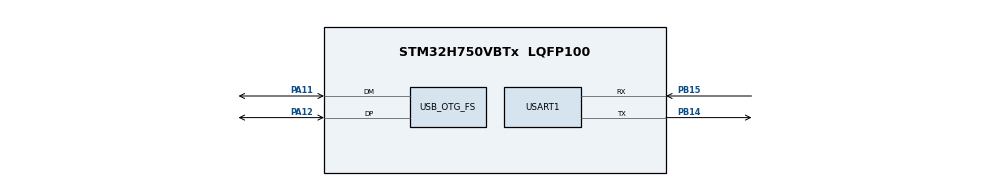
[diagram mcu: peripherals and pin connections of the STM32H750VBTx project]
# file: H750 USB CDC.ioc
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Mcu.Family=STM32H7
Mcu.Name=STM32H750VBTx
Mcu.Package=LQFP100
NVIC.OTG_FS_IRQn=true\:0\:0\:false\:false\:true\:false\:true
NVIC.PriorityGroup=NVIC_PRIORITYGROUP_4
NVIC.USART1_IRQn=true\:0\:0\:false\:false\:true\:true\:true
PA11.GPIO_Speed=GPIO_SPEED_FREQ_VERY_HIGH
PA11.Mode=Device_Only
PA11.Signal=USB_OTG_FS_DM
PA12.GPIO_Speed=GPIO_SPEED_FREQ_VERY_HIGH
PA12.Mode=Device_Only
PA12.Signal=USB_OTG_FS_DP
PA13\ (JTMS/SWDIO).Mode=Serial_Wire
PA13\ (JTMS/SWDIO).Signal=DEBUG_JTMS-SWDIO
PA14\ (JTCK/SWCLK).Mode=Serial_Wire
PA14\ (JTCK/SWCLK).Signal=DEBUG_JTCK-SWCLK
PB14.Mode=Asynchronous
PB14.Signal=USART1_TX
PB15.Mode=Asynchronous
PB15.Signal=USART1_RX
PH0-OSC_IN\ (PH0).Mode=HSE-External-Oscillator
PH0-OSC_IN\ (PH0).Signal=RCC_OSC_IN
PH1-OSC_OUT\ (PH1).Mode=HSE-External-Oscillator
PH1-OSC_OUT\ (PH1).Signal=RCC_OSC_OUT
ProjectManager.HeapSize=0x200
ProjectManager.StackSize=0x400
ProjectManager.TargetToolchain=STM32CubeIDE
RCC.ADCFreq_Value=16125000
RCC.APB1Freq_Value=120000000
RCC.APB2Freq_Value=120000000
RCC.APB3Freq_Value=120000000
RCC.APB4Freq_Value=120000000
RCC.CortexFreq_Value=480000000
RCC.D1PPRE=RCC_APB3_DIV2
RCC.D2PPRE1=RCC_APB1_DIV2
RCC.D2PPRE2=RCC_APB2_DIV2
RCC.D3PPRE=RCC_APB4_DIV2
RCC.DIVM1=1
RCC.DIVN1=120
RCC.DIVQ1=20
RCC.HCLKFreq_Value=240000000
RCC.HPRE=RCC_HCLK_DIV2
RCC.HSE_VALUE=8000000
RCC.PLL1_VCI_Range=RCC_PLL1VCIRANGE_3
RCC.PLL2FRACN=0
RCC.PLL3FRACN=0
RCC.PLLFRACN=0
RCC.SYSCLKFreq_VALUE=480000000
RCC.SYSCLKSource=RCC_SYSCLKSOURCE_PLLCLK
RCC.USBFreq_Value=48000000
USART1.VirtualMode-Asynchronous=VM_ASYNC
USB_DEVICE.CLASS_NAME_FS=CDC
USB_DEVICE.VirtualMode-CDC_FS=Cdc
USB_DEVICE.VirtualModeFS=Cdc_FS
USB_OTG_FS.VirtualMode=Device_Only
VP_USB_DEVICE_VS_USB_DEVICE_CDC_FS.Mode=CDC_FS
board=custom

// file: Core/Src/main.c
/* USER CODE BEGIN Header */
/**
  ******************************************************************************
  * @file           : main.c
  * @brief          : Main program body
  ******************************************************************************
  * @attention
  *
  * <h2><center>&copy; Copyright (c) 2020 STMicroelectronics.
  * All rights reserved.</center></h2>
  *
  * This software component is licensed by ST under BSD 3-Clause license,
  * the "License"; You may not use this file except in compliance with the
  * License. You may obtain a copy of the License at:
  *                        opensource.org/licenses/BSD-3-Clause
  *
  ******************************************************************************
  */
/* USER CODE END Header */

#include "main.h"
#include "usart.h"
#include "usb_device.h"
#include "gpio.h"

/* USER CODE BEGIN Includes */
#include "usbd_cdc_if.h"

/* USER CODE END Includes */

/* USER CODE BEGIN PV */
  uint8_t UartRxBuffer[10];

/* USER CODE END PV */

void SystemClock_Config(void);

/* USER CODE BEGIN 0 */
void HAL_UART_RxCpltCallback(UART_HandleTypeDef *huart)
{
	CDC_Transmit_FS(UartRxBuffer, 1);
	HAL_UART_Receive_IT(&huart1, (uint8_t *)UartRxBuffer, 1);
}

/* USER CODE END 0 */

int main(void)
{

  /* MCU Configuration--------------------------------------------------------*/

  /* Reset of all peripherals, Initializes the Flash interface and the Systick. */
  HAL_Init();

  /* Configure the system clock */
  SystemClock_Config();

  /* Initialize all configured peripherals */
  MX_GPIO_Init();
  MX_USART1_UART_Init();
  MX_USB_DEVICE_Init();

  /* Infinite loop */
  /* USER CODE BEGIN WHILE */
 	HAL_UART_Receive_IT(&huart1, (uint8_t *)UartRxBuffer, 1);
  while (1)
  {
    /* USER CODE END WHILE */

  }
}

void SystemClock_Config(void)
{
  RCC_OscInitTypeDef RCC_OscInitStruct = {0};
  RCC_ClkInitTypeDef RCC_ClkInitStruct = {0};
  RCC_PeriphCLKInitTypeDef PeriphClkInitStruct = {0};

  /** Supply configuration update enable
  */
  HAL_PWREx_ConfigSupply(PWR_LDO_SUPPLY);
  /** Configure the main internal regulator output voltage
  */
  __HAL_PWR_VOLTAGESCALING_CONFIG(PWR_REGULATOR_VOLTAGE_SCALE0);

  while(!__HAL_PWR_GET_FLAG(PWR_FLAG_VOSRDY)) {}
  /** Initializes the CPU, AHB and APB busses clocks
  */
  RCC_OscInitStruct.OscillatorType = RCC_OSCILLATORTYPE_HSE;
  RCC_OscInitStruct.HSEState = RCC_HSE_ON;
  RCC_OscInitStruct.PLL.PLLState = RCC_PLL_ON;
  RCC_OscInitStruct.PLL.PLLSource = RCC_PLLSOURCE_HSE;
  RCC_OscInitStruct.PLL.PLLM = 1;
  RCC_OscInitStruct.PLL.PLLN = 120;
  RCC_OscInitStruct.PLL.PLLP = 2;
  RCC_OscInitStruct.PLL.PLLQ = 20;
  RCC_OscInitStruct.PLL.PLLR = 2;
  RCC_OscInitStruct.PLL.PLLRGE = RCC_PLL1VCIRANGE_3;
  RCC_OscInitStruct.PLL.PLLVCOSEL = RCC_PLL1VCOWIDE;
  RCC_OscInitStruct.PLL.PLLFRACN = 0;
  if (HAL_RCC_OscConfig(&RCC_OscInitStruct) != HAL_OK)
  {
    Error_Handler();
  }
  /** Initializes the CPU, AHB and APB busses clocks
  */
  RCC_ClkInitStruct.ClockType = RCC_CLOCKTYPE_HCLK|RCC_CLOCKTYPE_SYSCLK
                              |RCC_CLOCKTYPE_PCLK1|RCC_CLOCKTYPE_PCLK2
                              |RCC_CLOCKTYPE_D3PCLK1|RCC_CLOCKTYPE_D1PCLK1;
  RCC_ClkInitStruct.SYSCLKSource = RCC_SYSCLKSOURCE_PLLCLK;
  RCC_ClkInitStruct.SYSCLKDivider = RCC_SYSCLK_DIV1;
  RCC_ClkInitStruct.AHBCLKDivider = RCC_HCLK_DIV2;
  RCC_ClkInitStruct.APB3CLKDivider = RCC_APB3_DIV2;
  RCC_ClkInitStruct.APB1CLKDivider = RCC_APB1_DIV2;
  RCC_ClkInitStruct.APB2CLKDivider = RCC_APB2_DIV2;
  RCC_ClkInitStruct.APB4CLKDivider = RCC_APB4_DIV2;

  if (HAL_RCC_ClockConfig(&RCC_ClkInitStruct, FLASH_LATENCY_4) != HAL_OK)
  {
    Error_Handler();
  }
  PeriphClkInitStruct.PeriphClockSelection = RCC_PERIPHCLK_USART1|RCC_PERIPHCLK_USB;
  PeriphClkInitStruct.Usart16ClockSelection = RCC_USART16CLKSOURCE_D2PCLK2;
  PeriphClkInitStruct.UsbClockSelection = RCC_USBCLKSOURCE_PLL;
  if (HAL_RCCEx_PeriphCLKConfig(&PeriphClkInitStruct) != HAL_OK)
  {
    Error_Handler();
  }
  /** Enable USB Voltage detector
  */
  HAL_PWREx_EnableUSBVoltageDetector();
}

void Error_Handler(void)
{
}

/************************ (C) COPYRIGHT STMicroelectronics *****END OF FILE****/
